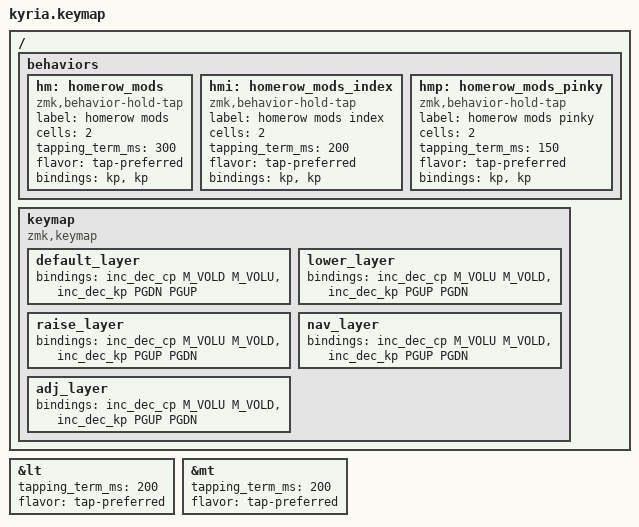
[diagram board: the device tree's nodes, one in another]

/*
 * Copyright (c) 2020 The ZMK Contributors
 *
 * SPDX-License-Identifier: MIT
 */

#include "keys-swedish.h"
#include <behaviors.dtsi>
#include <dt-bindings/zmk/bt.h>
#include <dt-bindings/zmk/ext_power.h>
#include <dt-bindings/zmk/keys.h>
#include <dt-bindings/zmk/outputs.h>

#define DEFAULT 0
#define LOWER 1
#define RAISE 2
#define NAV 3
#define ADJ 4

&lt {
  tapping_term_ms = <200>;
  flavor = "tap-preferred";
};
&mt {
  tapping_term_ms = <200>;
  flavor = "tap-preferred";
};
/ {
  behaviors {
  hm:
    homerow_mods {
      compatible = "zmk,behavior-hold-tap";
      label = "homerow mods";
#binding - cells = < 2>;
      tapping_term_ms = <300>;
      flavor = "tap-preferred";
      bindings = <&kp>, <&kp>;
    };
  hmi:
    homerow_mods_index {
      compatible = "zmk,behavior-hold-tap";
      label = "homerow mods index";
#binding - cells = < 2>;
      tapping_term_ms = <200>;
      flavor = "tap-preferred";
      bindings = <&kp>, <&kp>;
    };
  hmp:
    homerow_mods_pinky {
      compatible = "zmk,behavior-hold-tap";
      label = "homerow mods pinky";
#binding - cells = < 2>;
      tapping_term_ms = <150>;
      flavor = "tap-preferred";
      bindings = <&kp>, <&kp>;
    };
  };
};

/ {

  keymap {
    compatible = "zmk,keymap";

    default_layer {
      // ---------------------------------------------------------------------------------------------------------------------------------
      // |  ESC  |  Q  |  W  |  E   |  R   |  T   | |  Y   |  U    |  I    |  O
      // |   P   |   \  | |  TAB  |  A  |  S  |  D   |  F   |  G   | |  H   |  J
      // |  K    |  L   |   ;   |   '  | | SHIFT |  Z  |  X  |  C   |  V   |  B
      // | L SHIFT | L SHIFT |  | L SHIFT | L SHIFT |  N   |  M    |  ,    |  .
      // |   /   | CTRL |
      //                     | GUI  | DEL  | RET  |  SPACE  |   ESC   |  |   RET
      //                     |  SPACE  | TAB  | BSPC  | R-ALT |
      bindings =
          <&kp ESC & kp Q & kp W & kp E & kp R & kp T & kp Y & kp U & kp I &
           kp O & kp P & kp SE_AA & kp TAB & hmi LSFT A & hmi LCTL S &
           hm LALT D & hmi LGUI F & kp G & kp H & hmi LGUI J & hm LALT K &
           hm LCTL L & hmp LSFT SE_OE & kp SE_AE & kp LG(LC(A)) & kp Z & kp X &
           kp C & kp V & kp B & lt LOWER BKSP & lt LOWER SPC & lt RAISE RET &
           lt RAISE RET & kp N & kp M & kp COMMA & kp DOT & kp LS(CMMA) &
           kp DEL & none & none & none & kp BKSP & lt LOWER SPC & lt RAISE RET &
           mo RAISE & mo NAV & none & mo ADJ>;

      sensor - bindings = <&inc_dec_cp M_VOLD M_VOLU & inc_dec_kp PGDN PGUP>;
    };

    lower_layer {
      bindings =
          <&trans & trans & trans & trans & trans & trans & trans & kp N7 &
           kp N8 & kp N9 & trans & trans & kp F1 & kp F2 & kp F3 & kp F4 &
           kp F5 & kp F6 & trans & kp N4 & kp N5 & kp N6 & trans & trans &
           kp F7 & kp F8 & kp F9 & kp F10 & kp F11 & kp F12 & trans & trans &
           trans & trans & kp N0 & kp N1 & kp N2 & kp N3 & trans & trans &
           trans & trans & trans & trans & trans & trans & mo NAV & trans &
           trans & trans>;

      sensor - bindings = <&inc_dec_cp M_VOLU M_VOLD & inc_dec_kp PGUP PGDN>;
    };

    raise_layer {
      bindings =
          <&trans & kp SE_UNDS & kp SE_AMPR & kp SE_GRV & kp SE_LCBR &
           kp SE_RCBR & kp SE_LT & kp SE_GT & kp SE_EQL & kp SE_PLUS & trans &
           trans & trans & kp SE_MINS & kp SE_QUOT & kp SE_DQUO & kp SE_LPRN &
           kp SE_RPRN & kp SE_LBRC & kp SE_RBRC & kp SE_CLN & kp SE_SLSH &
           kp SE_AT & trans & kp LG(LC(M)) & kp SE_CIRC & kp SE_BSLS &
           kp SE_ASTR & kp SE_EXLM & kp SE_HASH & trans & trans & trans &
           trans & kp SE_PIPE & kp SE_QUES & kp SE_DLR & kp SE_PERC &
           kp SE_TILD & kp RCTL & trans & trans & trans & trans & mo NAV &
           trans & trans & trans & trans & trans>;

      sensor - bindings = <&inc_dec_cp M_VOLU M_VOLD & inc_dec_kp PGUP PGDN>;
    };

    nav_layer {
      bindings =
          <&trans & trans & trans & trans & trans & trans & kp HOME & kp PGDN &
           kp PGUP & kp END & trans & trans & trans & trans & trans & trans &
           trans & trans & kp LEFT & kp DOWN & kp UP & kp RIGHT & trans &
           trans & trans & trans & trans & trans & trans & trans & trans &
           trans & trans & trans & trans & trans & trans & trans & trans &
           trans & trans & trans & trans & trans & trans & trans & trans &
           trans & trans & trans>;

      sensor - bindings = <&inc_dec_cp M_VOLU M_VOLD & inc_dec_kp PGUP PGDN>;
    };

    adj_layer {
      bindings =
          <&bt BT_CLR & bt BT_PRV & bt BT_NXT & bt BT_SEL 0 & bt BT_SEL 1 &
           bt BT_SEL 2 & trans & trans & trans & trans & out OUT_TOG &
           ext_power EP_OFF & trans & trans & trans & trans & trans & trans &
           trans & trans & trans & trans & out OUT_BLE & ext_power EP_ON &
           trans & trans & trans & trans & trans & trans & trans & trans &
           trans & trans & trans & trans & trans & trans & out OUT_USB &
           ext_power EP_TOG & trans & trans & trans & trans & trans & trans &
           trans & trans & trans & trans>;

      sensor - bindings = <&inc_dec_cp M_VOLU M_VOLD & inc_dec_kp PGUP PGDN>;
    };
  };
};
